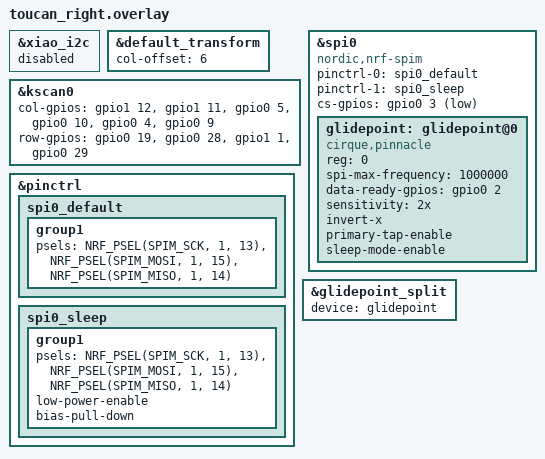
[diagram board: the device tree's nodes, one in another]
#include "toucan.dtsi"
#include <input/processors.dtsi>
#include <dt-bindings/zmk/input_transform.h>

&xiao_i2c {
    status = "disabled";
};

&default_transform {
    col-offset = <6>;
};

&kscan0 {
    col-gpios
    = <&gpio1 12 GPIO_ACTIVE_HIGH>
    , <&gpio1 11 GPIO_ACTIVE_HIGH>
    , <&gpio0 5 GPIO_ACTIVE_HIGH>
    , <&gpio0 10 GPIO_ACTIVE_HIGH>
    , <&gpio0 4 GPIO_ACTIVE_HIGH>
    , <&gpio0 9 GPIO_ACTIVE_HIGH>
    ;

    row-gpios
    = <&gpio0 19 (GPIO_ACTIVE_HIGH | GPIO_PULL_DOWN)>
    , <&gpio0 28 (GPIO_ACTIVE_HIGH | GPIO_PULL_DOWN)>
    , <&gpio1 1 (GPIO_ACTIVE_HIGH | GPIO_PULL_DOWN)>
    , <&gpio0 29 (GPIO_ACTIVE_HIGH | GPIO_PULL_DOWN)>
    ;
};

&pinctrl {
    spi0_default: spi0_default {
        group1 {
            psels = <NRF_PSEL(SPIM_SCK, 1, 13)>,
                <NRF_PSEL(SPIM_MOSI, 1, 15)>,
                <NRF_PSEL(SPIM_MISO, 1, 14)>;
        };
    };

     spi0_sleep: spi0_sleep {
        group1 {
            psels = <NRF_PSEL(SPIM_SCK, 1, 13)>,
                    <NRF_PSEL(SPIM_MOSI, 1, 15)>,
                    <NRF_PSEL(SPIM_MISO, 1, 14)>;
            low-power-enable;
            bias-pull-down; // minimize power leakage during sleep
        };
    };

};

&spi0 {
   compatible = "nordic,nrf-spim";
   status = "okay";
   pinctrl-0 = <&spi0_default>;
   pinctrl-1 = <&spi0_sleep>;
   pinctrl-names = "default", "sleep";
   cs-gpios = <&gpio0 3 (GPIO_ACTIVE_LOW | GPIO_PULL_UP)>;  // pull-up to ensure CS is !asserted when asleep
   // Uses the native Zephyr 4.1 cirque,pinnacle driver
   // (zephyr/dts/bindings/input/cirque,pinnacle-common.yaml).
   glidepoint:  glidepoint@0 {
        compatible = "cirque,pinnacle";
        reg = <0>;
        spi-max-frequency = <1000000>;
        status = "okay";
        data-ready-gpios = <&gpio0 2 GPIO_ACTIVE_HIGH>;
        sensitivity = "2x";
        invert-x;
        // Taps are opt-in with the native driver (the old module enabled them by default).
        primary-tap-enable;

        // Hardware low-power mode after 5s without touch (~300ms wake-up latency).
        // The old module's "sleep on ZMK idle" hook has no native equivalent, so without
        // this the trackpad never sleeps; disable it if the wake delay feels worse than
        // the battery cost.
        sleep-mode-enable;
    };
};

&glidepoint_split {
    device = <&glidepoint>;

    // Optional
    // input-processors = <&zip_xy_transform (INPUT_TRANSFORM_XY_SWAP | INPUT_TRANSFORM_X_INVERT | INPUT_TRANSFORM_Y_INVERT)>;
};
